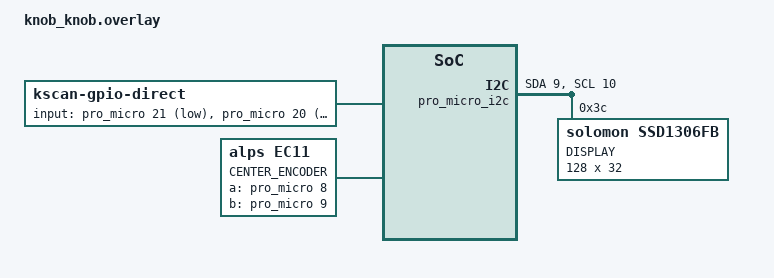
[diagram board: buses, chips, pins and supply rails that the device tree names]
/*
 * Copyright (c) 2022 The ZMK Contributors
 *
 * SPDX-License-Identifier: MIT
 */

/ {
    chosen {
        zmk,kscan = &kscan0;
        zephyr,display = &oled;
    };

    kscan0: kscan_0 {
        compatible = "zmk,kscan-gpio-direct";
        label = "KSCAN";

        // GPIO Pins :: Function    :: Corresponding Keymap index
        //        19 :: DOWN        :: 2
        //         8 :: CW          :: --
        //         9 :: CCW         :: -- 
        //        21 :: PUSH        :: 0
        //        20 :: UP          :: 1
        //        18 :: LEFT        :: 3
        //        15 :: RIGHT       :: 4
        input-gpios
            = <&pro_micro 21 (GPIO_ACTIVE_LOW | GPIO_PULL_UP)>
            , <&pro_micro 20 (GPIO_ACTIVE_LOW | GPIO_PULL_UP)>
            , <&pro_micro 19 (GPIO_ACTIVE_LOW | GPIO_PULL_UP)>
            , <&pro_micro 18 (GPIO_ACTIVE_LOW | GPIO_PULL_UP)>
            , <&pro_micro 15 (GPIO_ACTIVE_LOW | GPIO_PULL_UP)>
            ;
    };

    center_encoder: encoder_center {
        compatible = "alps,ec11";
        label = "CENTER_ENCODER";
        a-gpios = <&pro_micro 8 (GPIO_ACTIVE_HIGH | GPIO_PULL_UP)>;
        b-gpios = <&pro_micro 9 (GPIO_ACTIVE_HIGH | GPIO_PULL_UP)>;
        resolution = <1>; 
        status = "okay";
    };

    sensors {
        compatible = "zmk,keymap-sensors";
        sensors = <&center_encoder>;
    };
};

&pro_micro_i2c {
    status = "okay";
    sda-pin = <9>; // nice!nano pin 009
	scl-pin = <10>; // nice!nano pin 010

    oled: ssd1306@3c {
        compatible = "solomon,ssd1306fb";
        reg = <0x3c>;
        label = "DISPLAY";
        width = <128>;
        height = <32>;
        segment-offset = <0>;
        page-offset = <0>;
        display-offset = <0>;
        multiplex-ratio = <31>;
        segment-remap;
        com-invdir;
        com-sequential;
        prechargep = <0x22>;
    };
};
